# STM32MP157 register map
File version: 1.6
CPU: CM4 r0p1, little endian, no MPU, FPU, 4 interrupt priority bits
Registers are 32-bit, read-write, reset 0x0 unless marked. A register's access mark holds for its fields unless they carry their own. Offsets are from the block's base; [hi:lo] are bit positions; {n}, {i} and the like mark numbered series.

## GPIOA
Base 0x50002000
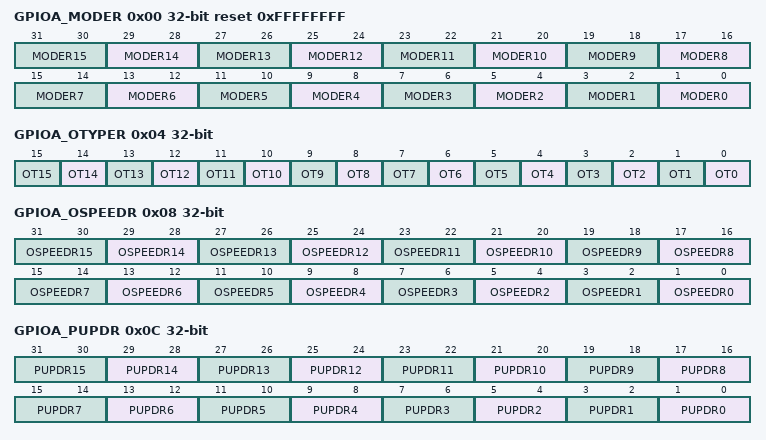
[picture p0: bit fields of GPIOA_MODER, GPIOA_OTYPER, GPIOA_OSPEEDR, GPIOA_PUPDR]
0x00 GPIOA_MODER reset 0xFFFFFFFF — GPIO port mode register
  [2n+1:2n] MODER{n} (n=0..15)
0x04 GPIOA_OTYPER — GPIO port output type register
  [n] OT{n} (n=0..15)
0x08 GPIOA_OSPEEDR — GPIO port output speed register
  [2n+1:2n] OSPEEDR{n} (n=0..15)
0x0C GPIOA_PUPDR — GPIO port pull-up/pull-down register
  [2n+1:2n] PUPDR{n} (n=0..15)
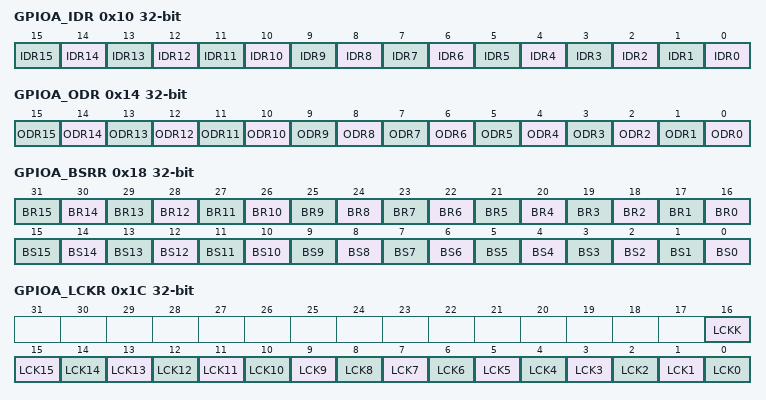
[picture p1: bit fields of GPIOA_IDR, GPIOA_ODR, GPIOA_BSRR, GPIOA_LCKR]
0x10 GPIOA_IDR ro — GPIO port input data register
  [n] IDR{n} (n=0..15)
0x14 GPIOA_ODR — GPIO port output data register
  [n] ODR{n} (n=0..15)
0x18 GPIOA_BSRR wo — GPIO port bit set/reset register
  [n+16] BR{n} (n=0..15), [n] BS{n} (n=0..15)
0x1C GPIOA_LCKR — This register is used to lock the configuration of the port bits when a correct write sequence is applied to bit 16 (LCKK). The value of bits [15:0] is used to lock the configuration of the GPIO. During the write sequence, the value of LCKR[15:0] must not change. When the LOCK sequence has been applied on a port bit, the value of this port bit can no longer be modified until the next MCU reset or peripheral reset. A specific write sequence is used to write to the GPIOx_LCKR register. Only word access (32-bit long) is allowed during this locking sequence. Each lock bit freezes a specific configuration register (control and alternate function registers).
  [16] LCKK, [n] LCK{n} (n=0..15)
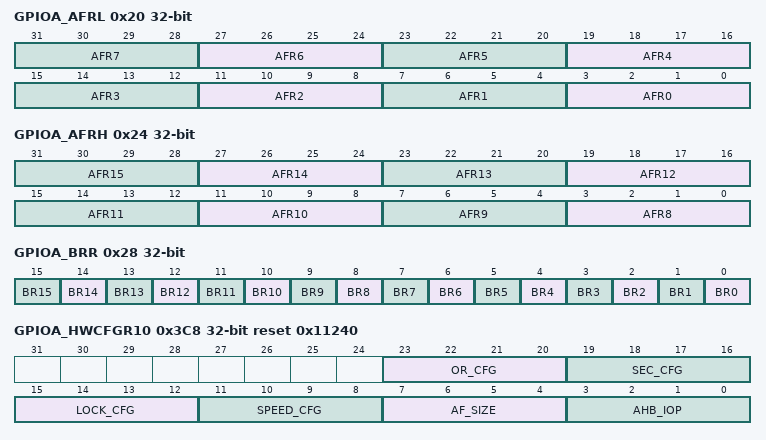
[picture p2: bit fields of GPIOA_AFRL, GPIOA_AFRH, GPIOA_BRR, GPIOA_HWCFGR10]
0x20 GPIOA_AFRL — GPIO alternate function low register
  [4n+3:4n] AFR{n} (n=0..7)
0x24 GPIOA_AFRH — GPIO alternate function high register
  [4n-29:4n-32] AFR{n} (n=8..15)
0x28 GPIOA_BRR wo — GPIO port bit reset register
  [n] BR{n} (n=0..15)
0x3C8 GPIOA_HWCFGR10 ro reset 0x11240 — For GPIOA, B, C, D, E, F, G, H, I, J and GPIOK: For GPIOZ:
  [23:20] OR_CFG, [19:16] SEC_CFG, [15:12] LOCK_CFG, [11:8] SPEED_CFG, [7:4] AF_SIZE, [3:0] AHB_IOP
0x3CC GPIOA_HWCFGR9 ro reset 0xFF — For GPIOA, B, C, D, E, F, G, H, I, and GPIOJ: For GPIOK and GPIOZ:
  [15:0] EN_IO
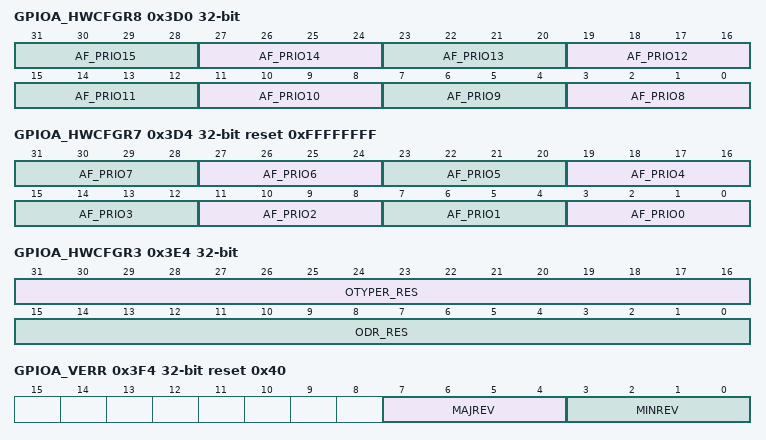
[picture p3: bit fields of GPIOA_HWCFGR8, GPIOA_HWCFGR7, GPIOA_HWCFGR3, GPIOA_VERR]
0x3D0 GPIOA_HWCFGR8 ro — For GPIOA, B, C, D, E, F, G, H, I, and GPIOJ: For GPIOK and GPIOZ:
  [4n-29:4n-32] AF_PRIO{n} (n=8..15)
0x3D4 GPIOA_HWCFGR7 ro reset 0xFFFFFFFF — GPIO hardware configuration register 7
  [4n+3:4n] AF_PRIO{n} (n=0..7)
0x3D8 GPIOA_HWCFGR6 ro reset 0xFFFFFFFF — GPIO hardware configuration register 6
  [31:0] MODER_RES
0x3DC GPIOA_HWCFGR5 ro — GPIO hardware configuration register 5
  [31:0] PUPDR_RES
0x3E0 GPIOA_HWCFGR4 ro — GPIO hardware configuration register 4
  [31:0] OSPEED_RES
0x3E4 GPIOA_HWCFGR3 ro — GPIO hardware configuration register 3
  [31:16] OTYPER_RES, [15:0] ODR_RES
0x3E8 GPIOA_HWCFGR2 ro — GPIO hardware configuration register 2
  [31:0] AFRL_RES
0x3EC GPIOA_HWCFGR1 ro — GPIO hardware configuration register 1
  [31:0] AFRH_RES
0x3F0 GPIOA_HWCFGR0 ro — GPIO hardware configuration register 0
  [15:0] OR_RES
0x3F4 GPIOA_VERR ro reset 0x40 — GPIO version register
  [7:4] MAJREV, [3:0] MINREV
0x3F8 GPIOA_IPIDR ro reset 0xF0002 — GPIO identification register
0x3FC GPIOA_SIDR ro reset 0xA3C5DD01 — GPIO size identification register

## GPIOB
Base 0x50003000
Registers as GPIOA (with GPIOA read as GPIOB); these are added or differ:
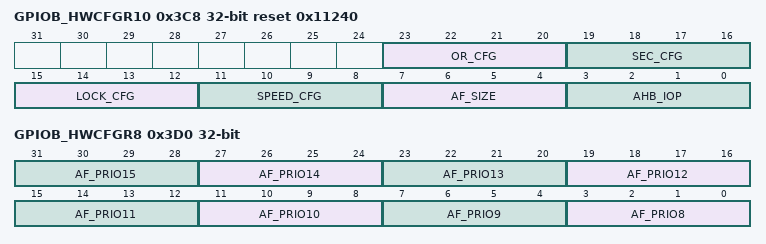
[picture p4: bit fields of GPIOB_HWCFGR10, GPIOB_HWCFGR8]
0x3C8 GPIOB_HWCFGR10 ro reset 0x11240 — For GPIOA, B, C, D, E, F, G, H, I, J and GPIOK: For GPIOZ:
  [23:20] OR_CFG, [19:16] SEC_CFG, [15:12] LOCK_CFG, [11:8] SPEED_CFG, [7:4] AF_SIZE, [3:0] AHB_IOP
0x3CC GPIOB_HWCFGR9 ro reset 0xFF — For GPIOA, B, C, D, E, F, G, H, I, and GPIOJ: For GPIOK and GPIOZ:
  [15:0] EN_IO
0x3D0 GPIOB_HWCFGR8 ro — For GPIOA, B, C, D, E, F, G, H, I, and GPIOJ: For GPIOK and GPIOZ:
  [4n-29:4n-32] AF_PRIO{n} (n=8..15)

## GPIOC
Base 0x50004000
Registers as GPIOB (with GPIOB read as GPIOC).

## GPIOD
Base 0x50005000
Registers as GPIOB (with GPIOB read as GPIOD).

## GPIOE
Base 0x50006000
Registers as GPIOB (with GPIOB read as GPIOE).

## GPIOF
Base 0x50007000
Registers as GPIOB (with GPIOB read as GPIOF).

## GPIOG
Base 0x50008000
Registers as GPIOB (with GPIOB read as GPIOG).

## GPIOH
Base 0x50009000
Registers as GPIOB (with GPIOB read as GPIOH).

## GPIOI
Base 0x5000A000
Registers as GPIOB (with GPIOB read as GPIOI).

## GPIOJ
Base 0x5000B000
Registers as GPIOB (with GPIOB read as GPIOJ); these are added or differ:
0x3CC GPIOJ_HWCFGR9 ro reset 0xFF — For GPIOA, B, C, D, E, F, G, H, I, and GPIOJ: For GPIOK and GPIOZ:
  [15:0] EN_IO
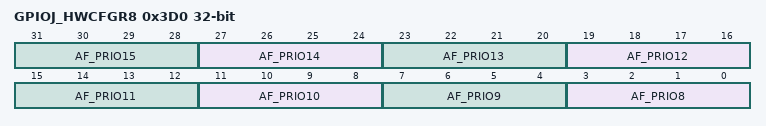
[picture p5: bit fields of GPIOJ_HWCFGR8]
0x3D0 GPIOJ_HWCFGR8 ro — For GPIOA, B, C, D, E, F, G, H, I, and GPIOJ: For GPIOK and GPIOZ:
  [4n-29:4n-32] AF_PRIO{n} (n=8..15)

## GPIOK
Base 0x5000C000
Registers as GPIOA (with GPIOA read as GPIOK); these are added or differ:
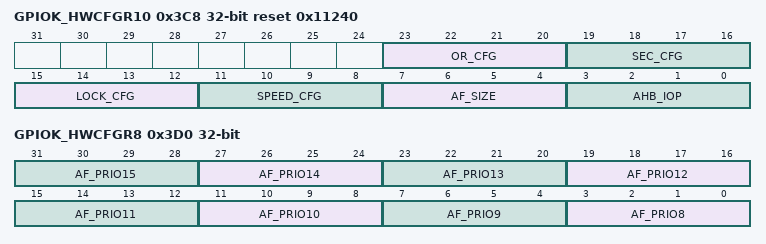
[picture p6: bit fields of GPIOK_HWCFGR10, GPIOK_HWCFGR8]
0x3C8 GPIOK_HWCFGR10 ro reset 0x11240 — For GPIOA, B, C, D, E, F, G, H, I, J and GPIOK: For GPIOZ:
  [23:20] OR_CFG, [19:16] SEC_CFG, [15:12] LOCK_CFG, [11:8] SPEED_CFG, [7:4] AF_SIZE, [3:0] AHB_IOP
0x3CC GPIOK_HWCFGR9 ro reset 0xFF — For GPIOA, B, C, D, E, F, G, H, I, and GPIOJ: For GPIOK and GPIOZ:
  [15:0] EN_IO
0x3D0 GPIOK_HWCFGR8 ro — For GPIOA, B, C, D, E, F, G, H, I, and GPIOJ: For GPIOK and GPIOZ:
  [4n-29:4n-32] AF_PRIO{n} (n=8..15)

## GPIOZ
Base 0x54004000
Registers as GPIOA (with GPIOA read as GPIOZ); these are added or differ:
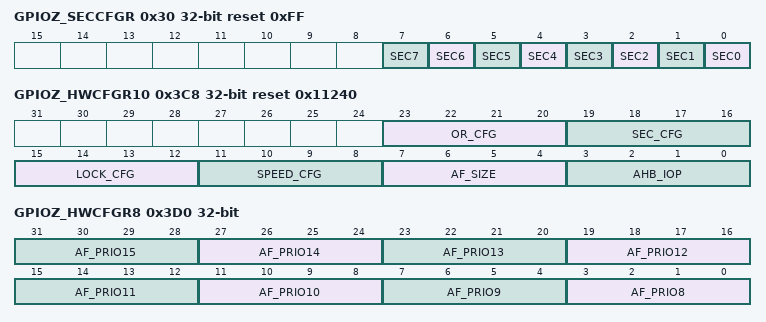
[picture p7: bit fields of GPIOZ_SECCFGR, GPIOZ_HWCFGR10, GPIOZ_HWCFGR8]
0x30 GPIOZ_SECCFGR wo reset 0xFF — This register provides write access security and can be written only by a secure access. It is used to configure a selected I/O as secure. A non-secure write access to this register is discarded.
  [n] SEC{n} (n=0..7)
0x3C8 GPIOZ_HWCFGR10 ro reset 0x11240 — For GPIOA, B, C, D, E, F, G, H, I, J and GPIOK: For GPIOZ:
  [23:20] OR_CFG, [19:16] SEC_CFG, [15:12] LOCK_CFG, [11:8] SPEED_CFG, [7:4] AF_SIZE, [3:0] AHB_IOP
0x3CC GPIOZ_HWCFGR9 ro reset 0xFF — For GPIOA, B, C, D, E, F, G, H, I, and GPIOJ: For GPIOK and GPIOZ:
  [15:0] EN_IO
0x3D0 GPIOZ_HWCFGR8 ro — For GPIOA, B, C, D, E, F, G, H, I, and GPIOJ: For GPIOK and GPIOZ:
  [4n-29:4n-32] AF_PRIO{n} (n=8..15)
